# PIC32MZ1025DAA169 register map
Vendor: Microchip
Registers are 32-bit, read-write, reset 0x0 unless marked. A register's access mark holds for its fields unless they carry their own. Addresses are absolute, and some are shared; only a register's first bit layout is shown; [hi:lo] are bit positions.

## DMAC
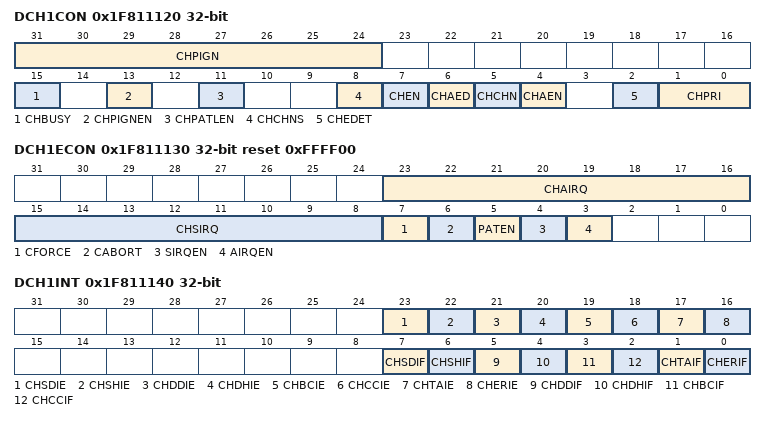
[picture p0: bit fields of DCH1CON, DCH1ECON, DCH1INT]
0x1F811120 DCH1CON reset not defined — (power-on value xxxxxxxx--------0-0-0--00000-000)
  [31:24] CHPIGN, [15] CHBUSY, [13] CHPIGNEN, [11] CHPATLEN, [8] CHCHNS, [7] CHEN, [6] CHAED, [5] CHCHN, [4] CHAEN, [2] CHEDET ro, [1:0] CHPRI
0x1F811130 DCH1ECON reset 0xFFFF00
  [23:16] CHAIRQ, [15:8] CHSIRQ, [7] CFORCE, [6] CABORT, [5] PATEN, [4] SIRQEN, [3] AIRQEN
0x1F811140 DCH1INT
  [23] CHSDIE, [22] CHSHIE, [21] CHDDIE, [20] CHDHIE, [19] CHBCIE, [18] CHCCIE, [17] CHTAIE, [16] CHERIE, [7] CHSDIF, [6] CHSHIF, [5] CHDDIF, [4] CHDHIF, [3] CHBCIF, [2] CHCCIF, [1] CHTAIF, [0] CHERIF
0x1F811150 DCH1SSA reset not defined — (power-on value xxxxxxxxxxxxxxxxxxxxxxxxxxxxxxxx)
  [31:0] CHSSA
0x1F811160 DCH1DSA reset not defined — (power-on value xxxxxxxxxxxxxxxxxxxxxxxxxxxxxxxx)
  [31:0] CHDSA
0x1F811170 DCH1SSIZ reset not defined — (power-on value ----------------xxxxxxxxxxxxxxxx)
  [15:0] CHSSIZ
0x1F811180 DCH1DSIZ reset not defined — (power-on value ----------------xxxxxxxxxxxxxxxx)
  [15:0] CHDSIZ
0x1F811190 DCH1SPTR
  [15:0] CHSPTR
0x1F8111A0 DCH1DPTR
  [15:0] CHDPTR
0x1F8111B0 DCH1CSIZ reset not defined — (power-on value ----------------xxxxxxxxxxxxxxxx)
  [15:0] CHCSIZ
0x1F8111C0 DCH1CPTR
  [15:0] CHCPTR
0x1F8111D0 DCH1DAT reset not defined — (power-on value ----------------xxxxxxxxxxxxxxxx)
  [15:0] CHPDAT

## I2C1
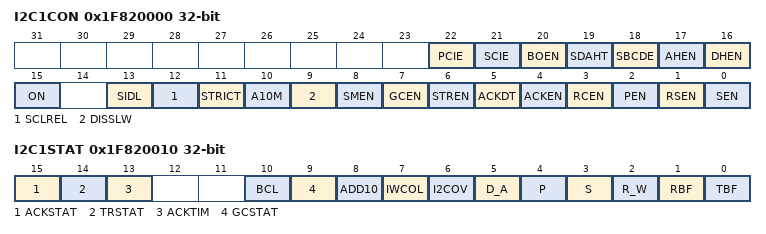
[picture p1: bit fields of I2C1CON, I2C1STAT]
0x1F820000 I2C1CON reset not defined — (power-on value ---------00000000x01000000000000)
  [22] PCIE, [21] SCIE, [20] BOEN, [19] SDAHT, [18] SBCDE, [17] AHEN, [16] DHEN, [15] ON, [13] SIDL, [12] SCLREL, [11] STRICT, [10] A10M, [9] DISSLW, [8] SMEN, [7] GCEN, [6] STREN, [5] ACKDT, [4] ACKEN, [3] RCEN, [2] PEN, [1] RSEN, [0] SEN
0x1F820010 I2C1STAT
  [15] ACKSTAT ro
  [14] TRSTAT ro
  [13] ACKTIM ro
  [10] BCL — (can only be cleared)
  [9] GCSTAT ro
  [8] ADD10 ro
  [7] IWCOL — (can only be cleared)
  [6] I2COV — (can only be cleared)
  [5] D_A ro
  [4] P — (can only be cleared)
  [3] S — (can only be cleared)
  [2] R_W ro
  [1] RBF ro
  [0] TBF ro
0x1F820020 I2C1ADD
  [9:0] I2CADD
0x1F820030 I2C1MSK
  [9:0] I2CMSK
0x1F820040 I2C1BRG
  [15:0] I2CBRG
0x1F820050 I2C1TRN wo reset 0xFF
  [7:0] I2CTRN
0x1F820060 I2C1RCV ro
  [7:0] I2CRCV

## I2C2
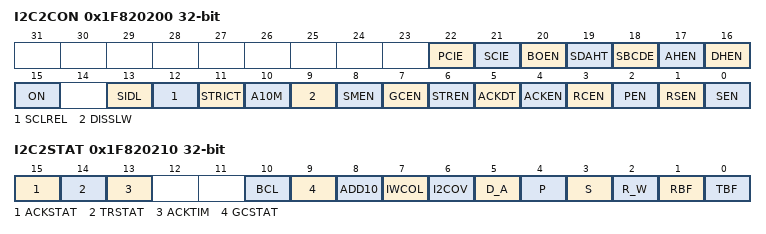
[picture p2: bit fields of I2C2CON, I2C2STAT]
0x1F820200 I2C2CON reset not defined — (power-on value ---------00000000x01000000000000)
  [22] PCIE, [21] SCIE, [20] BOEN, [19] SDAHT, [18] SBCDE, [17] AHEN, [16] DHEN, [15] ON, [13] SIDL, [12] SCLREL, [11] STRICT, [10] A10M, [9] DISSLW, [8] SMEN, [7] GCEN, [6] STREN, [5] ACKDT, [4] ACKEN, [3] RCEN, [2] PEN, [1] RSEN, [0] SEN
0x1F820210 I2C2STAT
  [15] ACKSTAT ro
  [14] TRSTAT ro
  [13] ACKTIM ro
  [10] BCL — (can only be cleared)
  [9] GCSTAT ro
  [8] ADD10 ro
  [7] IWCOL — (can only be cleared)
  [6] I2COV — (can only be cleared)
  [5] D_A ro
  [4] P — (can only be cleared)
  [3] S — (can only be cleared)
  [2] R_W ro
  [1] RBF ro
  [0] TBF ro
0x1F820220 I2C2ADD
  [9:0] I2CADD
0x1F820230 I2C2MSK
  [9:0] I2CMSK
0x1F820240 I2C2BRG
  [15:0] I2CBRG
0x1F820250 I2C2TRN wo reset 0xFF
  [7:0] I2CTRN
0x1F820260 I2C2RCV ro
  [7:0] I2CRCV

## I2C3
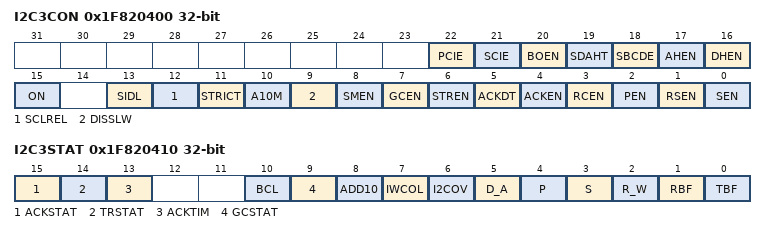
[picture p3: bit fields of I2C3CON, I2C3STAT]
0x1F820400 I2C3CON reset not defined — (power-on value ---------00000000x01000000000000)
  [22] PCIE, [21] SCIE, [20] BOEN, [19] SDAHT, [18] SBCDE, [17] AHEN, [16] DHEN, [15] ON, [13] SIDL, [12] SCLREL, [11] STRICT, [10] A10M, [9] DISSLW, [8] SMEN, [7] GCEN, [6] STREN, [5] ACKDT, [4] ACKEN, [3] RCEN, [2] PEN, [1] RSEN, [0] SEN
0x1F820410 I2C3STAT
  [15] ACKSTAT ro
  [14] TRSTAT ro
  [13] ACKTIM ro
  [10] BCL — (can only be cleared)
  [9] GCSTAT ro
  [8] ADD10 ro
  [7] IWCOL — (can only be cleared)
  [6] I2COV — (can only be cleared)
  [5] D_A ro
  [4] P — (can only be cleared)
  [3] S — (can only be cleared)
  [2] R_W ro
  [1] RBF ro
  [0] TBF ro
0x1F820420 I2C3ADD
  [9:0] I2CADD
0x1F820430 I2C3MSK
  [9:0] I2CMSK
0x1F820440 I2C3BRG
  [15:0] I2CBRG
0x1F820450 I2C3TRN wo reset 0xFF
  [7:0] I2CTRN
0x1F820460 I2C3RCV ro
  [7:0] I2CRCV
